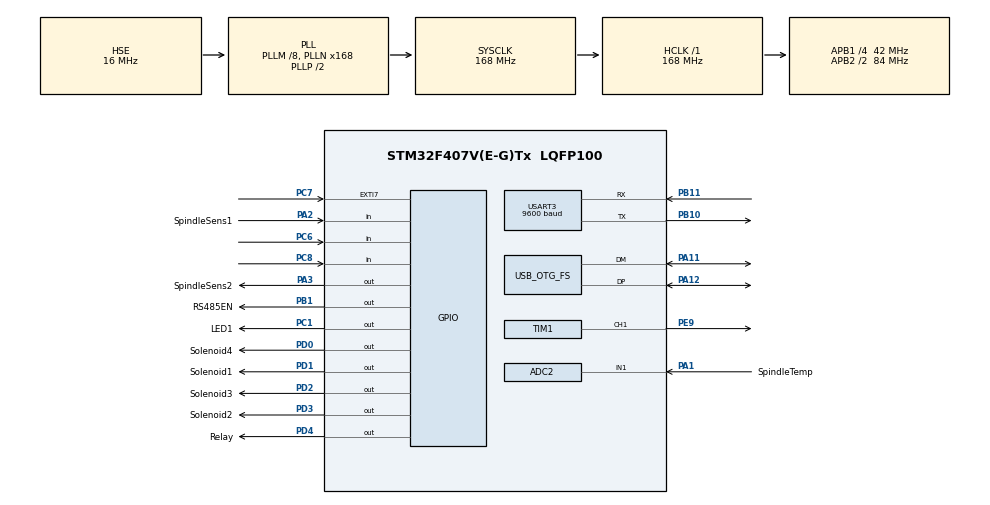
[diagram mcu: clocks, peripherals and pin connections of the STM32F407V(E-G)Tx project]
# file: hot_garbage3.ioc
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Mcu.Family=STM32F4
PA2.GPIO_PuPd=GPIO_NOPULL
PH0-OSC_IN.Signal=RCC_OSC_IN
RCC.CortexFreq_Value=168000000
ADC2.SamplingTime-1\#ChannelRegularConversion=ADC_SAMPLETIME_3CYCLES
PB10.Mode=Asynchronous
PD0.GPIO_Label=Solenoid4
PA11.Mode=Device_Only
PB11.Signal=USART3_RX
RCC.SYSCLKSource=RCC_SYSCLKSOURCE_PLLCLK
ProjectManager.StackSize=0x400
PA12.Signal=USB_OTG_FS_DP
USART3.BaudRate=9600
RCC.HCLKFreq_Value=168000000
PD4.Signal=GPIO_Output
RCC.APB2TimFreq_Value=168000000
TIM3.Period=10-1
PC7.Signal=GPXTI7
PD0.Signal=GPIO_Output
RCC.AHBFreq_Value=168000000
PH0-OSC_IN.Mode=HSE-External-Oscillator
RCC.HSE_VALUE=16000000
PB3.Mode=Trace_Asynchronous_SW
PD1.GPIO_Label=Solenoid1
TIM1.Channel-PWM\ Generation1\ CH1=TIM_CHANNEL_1
PE9.Signal=S_TIM1_CH1
PA14.Mode=Trace_Asynchronous_SW
TIM3.Prescaler=8400-1
PB1.GPIO_Label=RS485EN
VP_TIM1_VS_ClockSourceINT.Mode=Internal
PH1-OSC_OUT.Mode=HSE-External-Oscillator
PC7.GPIO_ModeDefaultEXTI=GPIO_MODE_IT_FALLING
Mcu.Package=LQFP100
PB1.Signal=GPIO_Output
PA2.GPIO_Label=SpindleSens1
ADC2.Channel-1\#ChannelRegularConversion=ADC_CHANNEL_1
USB_OTG_FS.VirtualMode=Device_Only
RCC.APB2CLKDivider=RCC_HCLK_DIV2
SH.ADCx_IN1.0=ADC2_IN1,IN1
RCC.APB1TimFreq_Value=84000000
PD3.GPIO_Label=Solenoid2
VP_TIM3_VS_ClockSourceINT.Mode=Internal
PA3.Signal=GPIO_Output
PD3.Signal=GPIO_Output
PC8.Signal=GPIO_Input
PC6.Signal=GPIO_Input
PD1.Signal=GPIO_Output
RCC.APB1CLKDivider=RCC_HCLK_DIV4
PA13.Signal=SYS_JTMS-SWDIO
SH.S_TIM1_CH1.0=TIM1_CH1,PWM Generation1 CH1
PB11.Mode=Asynchronous
ProjectManager.TargetToolchain=STM32CubeIDE
RCC.LSE_VALUE=32768
PA1.Signal=ADCx_IN1
PB10.Signal=USART3_TX
board=custom
RCC.VCOOutputFreq_Value=336000000
RCC.APB2Freq_Value=84000000
PD4.GPIO_Label=Relay
PC1.GPIO_Label=LED1
PA1.GPIO_Label=SpindleTemp
PH1-OSC_OUT.Signal=RCC_OSC_OUT
PA13.Mode=Trace_Asynchronous_SW
Mcu.Name=STM32F407V(E-G)Tx
PA2.Signal=GPIO_Input
RCC.48MHZClocksFreq_Value=48000000
PB3.Signal=SYS_JTDO-SWO
RCC.SYSCLKFreq_VALUE=168000000
PA12.Mode=Device_Only
ADC2.NbrOfConversionFlag=1
USART3.VirtualMode=VM_ASYNC
PA11.Signal=USB_OTG_FS_DM
NVIC.EXTI9_5_IRQn=true\:1\:0\:true\:false\:true\:true\:true
PA14.Signal=SYS_JTCK-SWCLK
ProjectManager.HeapSize=0x200
RCC.HSI_VALUE=16000000
RCC.PLLQ=7
NVIC.PriorityGroup=NVIC_PRIORITYGROUP_4
RCC.PLLM=8
RCC.PLLN=168
ADC2.Rank-1\#ChannelRegularConversion=1
PD2.Signal=GPIO_Output
RCC.APB1Freq_Value=42000000
VP_CRC_VS_CRC.Mode=CRC_Activate
PC1.Signal=GPIO_Output
PD2.GPIO_Label=Solenoid3
PA3.GPIO_Label=SpindleSens2

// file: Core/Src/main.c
/* USER CODE BEGIN Header */
/**
 ******************************************************************************
 * @file           : main.c
 * @brief          : Main program body
 ******************************************************************************
 * @attention
 *
 * <h2><center>&copy; Copyright (c) 2022 STMicroelectronics.
 * All rights reserved.</center></h2>
 *
 * This software component is licensed by ST under BSD 3-Clause license,
 * the "License"; You may not use this file except in compliance with the
 * License. You may obtain a copy of the License at:
 *                        opensource.org/licenses/BSD-3-Clause
 *
 ******************************************************************************
 */
/* USER CODE END Header */
#include "main.h"

/* USER CODE BEGIN Includes */
#include "modbus.h"
/* USER CODE END Includes */

ADC_HandleTypeDef hadc2;

CRC_HandleTypeDef hcrc;

TIM_HandleTypeDef htim1;
TIM_HandleTypeDef htim3;

UART_HandleTypeDef huart3;

PCD_HandleTypeDef hpcd_USB_OTG_FS;

void SystemClock_Config(void);
static void MX_GPIO_Init(void);
static void MX_ADC2_Init(void);
static void MX_USART3_UART_Init(void);
static void MX_TIM1_Init(void);
static void MX_TIM3_Init(void);
static void MX_CRC_Init(void);
static void MX_USB_OTG_FS_PCD_Init(void);

int main(void)
{

	/* MCU Configuration--------------------------------------------------------*/

	/* Reset of all peripherals, Initializes the Flash interface and the Systick. */
	HAL_Init();

	/* Configure the system clock */
	SystemClock_Config();

	/* Initialize all configured peripherals */
	MX_GPIO_Init();
	MX_ADC2_Init();
	MX_USART3_UART_Init();
	MX_TIM1_Init();
	MX_TIM3_Init();
	MX_CRC_Init();
	MX_USB_OTG_FS_PCD_Init();
	/* USER CODE BEGIN 2 */
	uint16_t registers[20] = { 0 };
	uint16_t registersOld[20] = { 0 };
	/* USER CODE END 2 */

	/* Infinite loop */
	while (1)
	{
		handleComms(&huart3, registers);

		//handle GPIO writes
		for (int i = 0; i < 5; i++)
		{
			//check if there is a change

			if (registers[i] != registersOld[i])
			{
				//something changed
				HAL_GPIO_WritePin(GPIOD, i, registers[i]);

			}

		}

		HAL_GPIO_WritePin(LED1_GPIO_Port, LED1_Pin, registers[5]);

		//handle spindle sensors
		//don't even bother checking lol
		registers[6] = HAL_GPIO_ReadPin(SpindleSens1_GPIO_Port,
		SpindleSens1_Pin);
		registers[7] = HAL_GPIO_ReadPin(SpindleSens2_GPIO_Port,
		SpindleSens2_Pin);

		HAL_ADC_Start(&hadc2);
		HAL_ADC_PollForConversion(&hadc2, 5);
		registers[8] = (uint16_t) HAL_ADC_GetValue(&hadc2);

	}
	/* USER CODE END 3 */
}

void SystemClock_Config(void)
{
	RCC_OscInitTypeDef RCC_OscInitStruct = { 0 };
	RCC_ClkInitTypeDef RCC_ClkInitStruct = { 0 };

	/** Configure the main internal regulator output voltage
	 */
	__HAL_RCC_PWR_CLK_ENABLE();
	__HAL_PWR_VOLTAGESCALING_CONFIG(PWR_REGULATOR_VOLTAGE_SCALE1);
	/** Initializes the RCC Oscillators according to the specified parameters
	 * in the RCC_OscInitTypeDef structure.
	 */
	RCC_OscInitStruct.OscillatorType = RCC_OSCILLATORTYPE_HSE;
	RCC_OscInitStruct.HSEState = RCC_HSE_ON;
	RCC_OscInitStruct.PLL.PLLState = RCC_PLL_ON;
	RCC_OscInitStruct.PLL.PLLSource = RCC_PLLSOURCE_HSE;
	RCC_OscInitStruct.PLL.PLLM = 8;
	RCC_OscInitStruct.PLL.PLLN = 168;
	RCC_OscInitStruct.PLL.PLLP = RCC_PLLP_DIV2;
	RCC_OscInitStruct.PLL.PLLQ = 7;
	if (HAL_RCC_OscConfig(&RCC_OscInitStruct) != HAL_OK)
	{
		Error_Handler();
	}
	/** Initializes the CPU, AHB and APB buses clocks
	 */
	RCC_ClkInitStruct.ClockType = RCC_CLOCKTYPE_HCLK | RCC_CLOCKTYPE_SYSCLK
			| RCC_CLOCKTYPE_PCLK1 | RCC_CLOCKTYPE_PCLK2;
	RCC_ClkInitStruct.SYSCLKSource = RCC_SYSCLKSOURCE_PLLCLK;
	RCC_ClkInitStruct.AHBCLKDivider = RCC_SYSCLK_DIV1;
	RCC_ClkInitStruct.APB1CLKDivider = RCC_HCLK_DIV4;
	RCC_ClkInitStruct.APB2CLKDivider = RCC_HCLK_DIV2;

	if (HAL_RCC_ClockConfig(&RCC_ClkInitStruct, FLASH_LATENCY_5) != HAL_OK)
	{
		Error_Handler();
	}
}

static void MX_ADC2_Init(void)
{

	ADC_ChannelConfTypeDef sConfig = { 0 };

	/** Configure the global features of the ADC (Clock, Resolution, Data Alignment and number of conversion)
	 */
	hadc2.Instance = ADC2;
	hadc2.Init.ClockPrescaler = ADC_CLOCK_SYNC_PCLK_DIV4;
	hadc2.Init.Resolution = ADC_RESOLUTION_12B;
	hadc2.Init.ScanConvMode = DISABLE;
	hadc2.Init.ContinuousConvMode = DISABLE;
	hadc2.Init.DiscontinuousConvMode = DISABLE;
	hadc2.Init.ExternalTrigConvEdge = ADC_EXTERNALTRIGCONVEDGE_NONE;
	hadc2.Init.ExternalTrigConv = ADC_SOFTWARE_START;
	hadc2.Init.DataAlign = ADC_DATAALIGN_RIGHT;
	hadc2.Init.NbrOfConversion = 1;
	hadc2.Init.DMAContinuousRequests = DISABLE;
	hadc2.Init.EOCSelection = ADC_EOC_SINGLE_CONV;
	if (HAL_ADC_Init(&hadc2) != HAL_OK)
	{
		Error_Handler();
	}
	/** Configure for the selected ADC regular channel its corresponding rank in the sequencer and its sample time.
	 */
	sConfig.Channel = ADC_CHANNEL_1;
	sConfig.Rank = 1;
	sConfig.SamplingTime = ADC_SAMPLETIME_3CYCLES;
	if (HAL_ADC_ConfigChannel(&hadc2, &sConfig) != HAL_OK)
	{
		Error_Handler();
	}

}

static void MX_CRC_Init(void)
{

	hcrc.Instance = CRC;
	if (HAL_CRC_Init(&hcrc) != HAL_OK)
	{
		Error_Handler();
	}

}

static void MX_TIM1_Init(void)
{

	TIM_ClockConfigTypeDef sClockSourceConfig = { 0 };
	TIM_MasterConfigTypeDef sMasterConfig = { 0 };
	TIM_OC_InitTypeDef sConfigOC = { 0 };
	TIM_BreakDeadTimeConfigTypeDef sBreakDeadTimeConfig = { 0 };

	htim1.Instance = TIM1;
	htim1.Init.Prescaler = 0;
	htim1.Init.CounterMode = TIM_COUNTERMODE_UP;
	htim1.Init.Period = 65535;
	htim1.Init.ClockDivision = TIM_CLOCKDIVISION_DIV1;
	htim1.Init.RepetitionCounter = 0;
	htim1.Init.AutoReloadPreload = TIM_AUTORELOAD_PRELOAD_DISABLE;
	if (HAL_TIM_Base_Init(&htim1) != HAL_OK)
	{
		Error_Handler();
	}
	sClockSourceConfig.ClockSource = TIM_CLOCKSOURCE_INTERNAL;
	if (HAL_TIM_ConfigClockSource(&htim1, &sClockSourceConfig) != HAL_OK)
	{
		Error_Handler();
	}
	if (HAL_TIM_PWM_Init(&htim1) != HAL_OK)
	{
		Error_Handler();
	}
	sMasterConfig.MasterOutputTrigger = TIM_TRGO_RESET;
	sMasterConfig.MasterSlaveMode = TIM_MASTERSLAVEMODE_DISABLE;
	if (HAL_TIMEx_MasterConfigSynchronization(&htim1, &sMasterConfig) != HAL_OK)
	{
		Error_Handler();
	}
	sConfigOC.OCMode = TIM_OCMODE_PWM1;
	sConfigOC.Pulse = 0;
	sConfigOC.OCPolarity = TIM_OCPOLARITY_HIGH;
	sConfigOC.OCNPolarity = TIM_OCNPOLARITY_HIGH;
	sConfigOC.OCFastMode = TIM_OCFAST_DISABLE;
	sConfigOC.OCIdleState = TIM_OCIDLESTATE_RESET;
	sConfigOC.OCNIdleState = TIM_OCNIDLESTATE_RESET;
	if (HAL_TIM_PWM_ConfigChannel(&htim1, &sConfigOC, TIM_CHANNEL_1) != HAL_OK)
	{
		Error_Handler();
	}
	sBreakDeadTimeConfig.OffStateRunMode = TIM_OSSR_DISABLE;
	sBreakDeadTimeConfig.OffStateIDLEMode = TIM_OSSI_DISABLE;
	sBreakDeadTimeConfig.LockLevel = TIM_LOCKLEVEL_OFF;
	sBreakDeadTimeConfig.DeadTime = 0;
	sBreakDeadTimeConfig.BreakState = TIM_BREAK_DISABLE;
	sBreakDeadTimeConfig.BreakPolarity = TIM_BREAKPOLARITY_HIGH;
	sBreakDeadTimeConfig.AutomaticOutput = TIM_AUTOMATICOUTPUT_DISABLE;
	if (HAL_TIMEx_ConfigBreakDeadTime(&htim1, &sBreakDeadTimeConfig) != HAL_OK)
	{
		Error_Handler();
	}
	HAL_TIM_MspPostInit(&htim1);

}

static void MX_TIM3_Init(void)
{

	TIM_ClockConfigTypeDef sClockSourceConfig = { 0 };
	TIM_MasterConfigTypeDef sMasterConfig = { 0 };

	htim3.Instance = TIM3;
	htim3.Init.Prescaler = 8400 - 1;
	htim3.Init.CounterMode = TIM_COUNTERMODE_UP;
	htim3.Init.Period = 10 - 1;
	htim3.Init.ClockDivision = TIM_CLOCKDIVISION_DIV1;
	htim3.Init.AutoReloadPreload = TIM_AUTORELOAD_PRELOAD_DISABLE;
	if (HAL_TIM_Base_Init(&htim3) != HAL_OK)
	{
		Error_Handler();
	}
	sClockSourceConfig.ClockSource = TIM_CLOCKSOURCE_INTERNAL;
	if (HAL_TIM_ConfigClockSource(&htim3, &sClockSourceConfig) != HAL_OK)
	{
		Error_Handler();
	}
	sMasterConfig.MasterOutputTrigger = TIM_TRGO_RESET;
	sMasterConfig.MasterSlaveMode = TIM_MASTERSLAVEMODE_DISABLE;
	if (HAL_TIMEx_MasterConfigSynchronization(&htim3, &sMasterConfig) != HAL_OK)
	{
		Error_Handler();
	}

}

static void MX_USART3_UART_Init(void)
{

	huart3.Instance = USART3;
	huart3.Init.BaudRate = 9600;
	huart3.Init.WordLength = UART_WORDLENGTH_8B;
	huart3.Init.StopBits = UART_STOPBITS_1;
	huart3.Init.Parity = UART_PARITY_NONE;
	huart3.Init.Mode = UART_MODE_TX_RX;
	huart3.Init.HwFlowCtl = UART_HWCONTROL_NONE;
	huart3.Init.OverSampling = UART_OVERSAMPLING_16;
	if (HAL_UART_Init(&huart3) != HAL_OK)
	{
		Error_Handler();
	}

}

static void MX_USB_OTG_FS_PCD_Init(void)
{

	hpcd_USB_OTG_FS.Instance = USB_OTG_FS;
	hpcd_USB_OTG_FS.Init.dev_endpoints = 4;
	hpcd_USB_OTG_FS.Init.speed = PCD_SPEED_FULL;
	hpcd_USB_OTG_FS.Init.dma_enable = DISABLE;
	hpcd_USB_OTG_FS.Init.phy_itface = PCD_PHY_EMBEDDED;
	hpcd_USB_OTG_FS.Init.Sof_enable = DISABLE;
	hpcd_USB_OTG_FS.Init.low_power_enable = DISABLE;
	hpcd_USB_OTG_FS.Init.lpm_enable = DISABLE;
	hpcd_USB_OTG_FS.Init.vbus_sensing_enable = DISABLE;
	hpcd_USB_OTG_FS.Init.use_dedicated_ep1 = DISABLE;
	if (HAL_PCD_Init(&hpcd_USB_OTG_FS) != HAL_OK)
	{
		Error_Handler();
	}

}

static void MX_GPIO_Init(void)
{
	GPIO_InitTypeDef GPIO_InitStruct = { 0 };

	/* GPIO Ports Clock Enable */
	__HAL_RCC_GPIOH_CLK_ENABLE();
	__HAL_RCC_GPIOC_CLK_ENABLE();
	__HAL_RCC_GPIOA_CLK_ENABLE();
	__HAL_RCC_GPIOB_CLK_ENABLE();
	__HAL_RCC_GPIOE_CLK_ENABLE();
	__HAL_RCC_GPIOD_CLK_ENABLE();

	/*Configure GPIO pin Output Level */
	HAL_GPIO_WritePin(LED1_GPIO_Port, LED1_Pin, GPIO_PIN_RESET);

	/*Configure GPIO pin Output Level */
	HAL_GPIO_WritePin(SpindleSens2_GPIO_Port, SpindleSens2_Pin, GPIO_PIN_RESET);

	/*Configure GPIO pin Output Level */
	HAL_GPIO_WritePin(RS485EN_GPIO_Port, RS485EN_Pin, GPIO_PIN_RESET);

	/*Configure GPIO pin Output Level */
	HAL_GPIO_WritePin(GPIOD,
	Solenoid4_Pin | Solenoid1_Pin | Solenoid3_Pin | Solenoid2_Pin | Relay_Pin,
			GPIO_PIN_RESET);

	/*Configure GPIO pin : LED1_Pin */
	GPIO_InitStruct.Pin = LED1_Pin;
	GPIO_InitStruct.Mode = GPIO_MODE_OUTPUT_PP;
	GPIO_InitStruct.Pull = GPIO_NOPULL;
	GPIO_InitStruct.Speed = GPIO_SPEED_FREQ_LOW;
	HAL_GPIO_Init(LED1_GPIO_Port, &GPIO_InitStruct);

	/*Configure GPIO pin : SpindleSens1_Pin */
	GPIO_InitStruct.Pin = SpindleSens1_Pin;
	GPIO_InitStruct.Mode = GPIO_MODE_INPUT;
	GPIO_InitStruct.Pull = GPIO_NOPULL;
	HAL_GPIO_Init(SpindleSens1_GPIO_Port, &GPIO_InitStruct);

	/*Configure GPIO pin : SpindleSens2_Pin */
	GPIO_InitStruct.Pin = SpindleSens2_Pin;
	GPIO_InitStruct.Mode = GPIO_MODE_OUTPUT_PP;
	GPIO_InitStruct.Pull = GPIO_NOPULL;
	GPIO_InitStruct.Speed = GPIO_SPEED_FREQ_LOW;
	HAL_GPIO_Init(SpindleSens2_GPIO_Port, &GPIO_InitStruct);

	/*Configure GPIO pin : RS485EN_Pin */
	GPIO_InitStruct.Pin = RS485EN_Pin;
	GPIO_InitStruct.Mode = GPIO_MODE_OUTPUT_PP;
	GPIO_InitStruct.Pull = GPIO_NOPULL;
	GPIO_InitStruct.Speed = GPIO_SPEED_FREQ_LOW;
	HAL_GPIO_Init(RS485EN_GPIO_Port, &GPIO_InitStruct);

	/*Configure GPIO pins : PC6 PC8 */
	GPIO_InitStruct.Pin = GPIO_PIN_6 | GPIO_PIN_8;
	GPIO_InitStruct.Mode = GPIO_MODE_INPUT;
	GPIO_InitStruct.Pull = GPIO_NOPULL;
	HAL_GPIO_Init(GPIOC, &GPIO_InitStruct);

	/*Configure GPIO pin : PC7 */
	GPIO_InitStruct.Pin = GPIO_PIN_7;
	GPIO_InitStruct.Mode = GPIO_MODE_IT_FALLING;
	GPIO_InitStruct.Pull = GPIO_NOPULL;
	HAL_GPIO_Init(GPIOC, &GPIO_InitStruct);

	/*Configure GPIO pins : Solenoid4_Pin Solenoid1_Pin Solenoid3_Pin Solenoid2_Pin
	 Relay_Pin */
	GPIO_InitStruct.Pin = Solenoid4_Pin | Solenoid1_Pin | Solenoid3_Pin
			| Solenoid2_Pin | Relay_Pin;
	GPIO_InitStruct.Mode = GPIO_MODE_OUTPUT_PP;
	GPIO_InitStruct.Pull = GPIO_NOPULL;
	GPIO_InitStruct.Speed = GPIO_SPEED_FREQ_LOW;
	HAL_GPIO_Init(GPIOD, &GPIO_InitStruct);

	/* EXTI interrupt init*/
	HAL_NVIC_SetPriority(EXTI9_5_IRQn, 1, 0);
	HAL_NVIC_EnableIRQ(EXTI9_5_IRQn);

}

void Error_Handler(void)
{
	__disable_irq();
	while (1)
	{
	}
}

/************************ (C) COPYRIGHT STMicroelectronics *****END OF FILE****/
